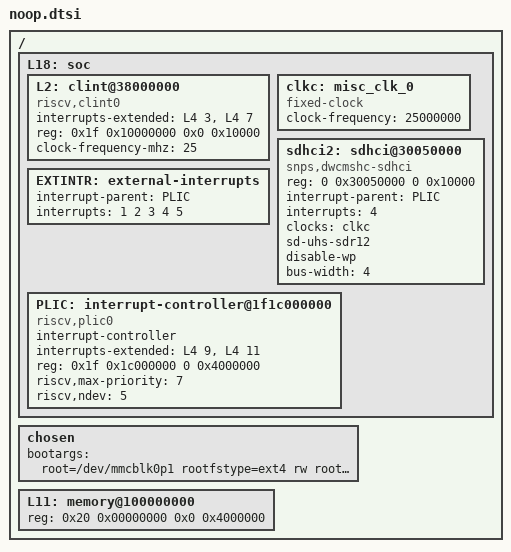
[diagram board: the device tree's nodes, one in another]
/dts-v1/;

/ {
    L18: soc {
        L2: clint@38000000 {
            compatible = "riscv,clint0";
            interrupts-extended = <&L4 3 &L4 7>;
            reg = <0x1f 0x10000000 0x0 0x10000>;
            //reg = <0x0 0x2000000 0x0 0x10000>;
            reg-names = "control";
            clock-frequency-mhz = <25>;
        };
        /*
        L14: serial@60000000 {
            compatible = "xilinx,uartlite";
            //interrupt-parent = <&L1>;
            interrupts = <3>;
            reg = <0x0 0x60000000 0x0 0x1000>;
            reg-names = "control";
        };
        */

        /*
        sdhci: mmc {
            compatible = "nemu-sdhost";
            reg = <0x0 0x40002000 0x0 0x1000>;
        };
        */


        clkc: misc_clk_0 {
            #clock-cells = <0>;
            clock-frequency = <25000000>;
            compatible = "fixed-clock";
        };



        sdhci2: sdhci@30050000 {
            compatible = "snps,dwcmshc-sdhci";
            reg = <0 0x30050000 0 0x10000>;
            interrupt-parent = <&PLIC>;
            interrupts = <4>;
            clocks = <&clkc>;
            clock-names = "core";
            sd-uhs-sdr12;
            disable-wp;
            bus-width = <4>;
        };

        EXTINTR: external-interrupts {
            interrupt-parent = <&PLIC>;
            interrupts = <1 2 3 4 5>;
        };
        PLIC: interrupt-controller@1f1c000000 {
            #interrupt-cells = <1>;
            compatible = "riscv,plic0";
            interrupt-controller;
            interrupts-extended = <&L4 9 &L4 11>;
            //reg = <0 0xc000000 0 0x4000000>;
            reg = <0x1f 0x1c000000 0 0x4000000>;
            reg-names = "control";
            riscv,max-priority = <7>;
            riscv,ndev = <5>;
        };
    };

    chosen {
        bootargs = "root=/dev/mmcblk0p1 rootfstype=ext4 rw rootwait earlycon noinitrd";
    };

    L11: memory@100000000 {
        device_type = "memory";
        reg = <0x20 0x00000000 0x0 0x4000000>;
    };
};
